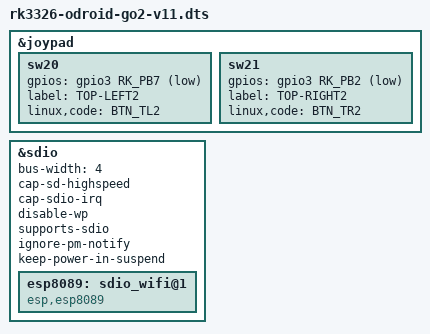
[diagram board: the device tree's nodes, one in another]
// SPDX-License-Identifier: (GPL-2.0+ OR MIT)
/*
 * Copyright (c) 2020 Fuzhou Rockchip Electronics Co., Ltd
 */

#include "rk3326-odroid-go2.dtsi"

&joypad {
	sw20 {
		gpios = <&gpio3 RK_PB7 GPIO_ACTIVE_LOW>;
		label = "TOP-LEFT2";
		linux,code = <BTN_TL2>;
	};

	sw21 {
		gpios = <&gpio3 RK_PB2 GPIO_ACTIVE_LOW>;
		label = "TOP-RIGHT2";
		linux,code = <BTN_TR2>;
	};
};

&sdio {
	bus-width = <4>;
	cap-sd-highspeed;
	cap-sdio-irq;
	disable-wp;
	supports-sdio;
	ignore-pm-notify;
	keep-power-in-suspend;
	status = "okay";

	esp8089: sdio_wifi@1 {
		compatible = "esp,esp8089";
	};
};
